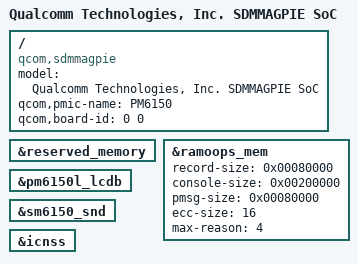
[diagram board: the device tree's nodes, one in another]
/* Copyright (c) 2018, The Linux Foundation. All rights reserved.
 *
 * This program is free software; you can redistribute it and/or modify
 * it under the terms of the GNU General Public License version 2 and
 * only version 2 as published by the Free Software Foundation.
 *
 * This program is distributed in the hope that it will be useful, but
 * WITHOUT ANY WARRANTY; without even the implied warranty of
 * MERCHANTABILITY or FITNESS FOR A PARTICULAR PURPOSE.  See the
 * GNU General Public License for more details.
 */

/dts-v1/;

#include "sdmmagpie.dtsi"

// Include non-overlayed xiaomi changes
#include "xiaomi/pm6150.dtsi"
#include "xiaomi/pm6150l.dtsi"
#include "xiaomi/sdmmagpie.dtsi"
#include "xiaomi/sdmmagpie-camera.dtsi"
#include "xiaomi/sdmmagpie-pinctrl.dtsi"
#include "xiaomi/sdmmagpie-regulator.dtsi"
#include "xiaomi/sdmmagpie-sde.dtsi"
#include "xiaomi/sdmmagpie-thermal.dtsi"

/ {
	model = "Qualcomm Technologies, Inc. SDMMAGPIE SoC";
	compatible = "qcom,sdmmagpie";
	qcom,pmic-name = "PM6150";
	qcom,board-id = <0 0>;
};

/*
 * Keep exactly one ramoops backend on Xiaomi SDMMAGPIE devices.
 * The original platform tree already reserves 4 MiB at 0x9d800000
 * explicitly for pstore.  The 0xb0000000 ramoops node was added later;
 * remove that duplicate and use the original platform reservation.
 */
&reserved_memory {
	/delete-node/ ramoops@b0000000;
};

/*
 * 4 MiB persistent RAM layout:
 *   1536 KiB dmesg (3 x 512 KiB records)
 *   2048 KiB console (continuously written)
 *    512 KiB pmsg
 * max-reason 4 includes panic, oops, emergency and restart dumps.
 * ECC is kept enabled for all persistent RAM zones.
 */
&ramoops_mem {
	record-size = <0x00080000>;
	console-size = <0x00200000>;
	pmsg-size = <0x00080000>;
	ecc-size = <16>;
	max-reason = <4>;
};

&pm6150l_lcdb {
	/delete-property/ qcom,voltage-step-ramp;
};

&sm6150_snd {
	/delete-property/ fsa4480-i2c-handle;
};

&icnss {
	/delete-property/ vdd-3.3-ch1-supply;
};
